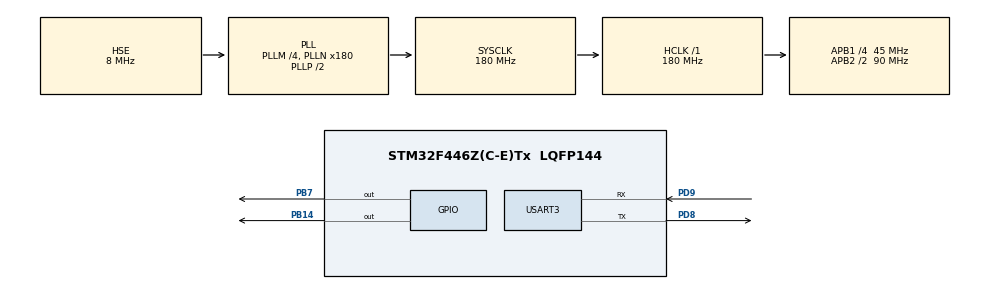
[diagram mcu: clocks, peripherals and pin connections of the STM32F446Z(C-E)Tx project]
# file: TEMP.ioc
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Dma.Request0=USART3_TX
Dma.USART3_TX.0.Direction=DMA_MEMORY_TO_PERIPH
Dma.USART3_TX.0.FIFOMode=DMA_FIFOMODE_DISABLE
Dma.USART3_TX.0.Instance=DMA1_Stream3
Dma.USART3_TX.0.MemDataAlignment=DMA_MDATAALIGN_BYTE
Dma.USART3_TX.0.MemInc=DMA_MINC_ENABLE
Dma.USART3_TX.0.Mode=DMA_NORMAL
Dma.USART3_TX.0.PeriphDataAlignment=DMA_PDATAALIGN_BYTE
Dma.USART3_TX.0.PeriphInc=DMA_PINC_DISABLE
Dma.USART3_TX.0.Priority=DMA_PRIORITY_LOW
Mcu.Family=STM32F4
Mcu.Name=STM32F446Z(C-E)Tx
Mcu.Package=LQFP144
NVIC.DMA1_Stream3_IRQn=true\:0\:0\:false\:false\:true\:false\:true\:true
NVIC.PriorityGroup=NVIC_PRIORITYGROUP_4
NVIC.USART3_IRQn=true\:0\:0\:false\:false\:true\:true\:true\:true
PB14.Signal=GPIO_Output
PB7.Signal=GPIO_Output
PD8.Mode=Asynchronous
PD8.Signal=USART3_TX
PD9.Mode=Asynchronous
PD9.Signal=USART3_RX
PH0-OSC_IN.Mode=HSE-External-Oscillator
PH0-OSC_IN.Signal=RCC_OSC_IN
PH1-OSC_OUT.Mode=HSE-External-Oscillator
PH1-OSC_OUT.Signal=RCC_OSC_OUT
ProjectManager.HeapSize=0x200
ProjectManager.StackSize=0x400
ProjectManager.TargetToolchain=STM32CubeIDE
RCC.AHBFreq_Value=180000000
RCC.APB1CLKDivider=RCC_HCLK_DIV4
RCC.APB1Freq_Value=45000000
RCC.APB1TimFreq_Value=90000000
RCC.APB2CLKDivider=RCC_HCLK_DIV2
RCC.APB2Freq_Value=90000000
RCC.APB2TimFreq_Value=180000000
RCC.CortexFreq_Value=180000000
RCC.HCLKFreq_Value=180000000
RCC.HSE_VALUE=8000000
RCC.PLLM=4
RCC.PLLN=180
RCC.PLLSourceVirtual=RCC_PLLSOURCE_HSE
RCC.SYSCLKFreq_VALUE=180000000
RCC.SYSCLKSource=RCC_SYSCLKSOURCE_PLLCLK
RCC.USBFreq_Value=180000000
RCC.VCOOutputFreq_Value=360000000
USART3.VirtualMode=VM_ASYNC
board=custom

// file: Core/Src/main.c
/* USER CODE BEGIN Header */
/**
  ******************************************************************************
  * @file           : main.c
  * @brief          : Main program body
  ******************************************************************************
  * @attention
  *
  * Copyright (c) 2026 STMicroelectronics.
  * All rights reserved.
  *
  * This software is licensed under terms that can be found in the LICENSE file
  * in the root directory of this software component.
  * If no LICENSE file comes with this software, it is provided AS-IS.
  *
  ******************************************************************************
  */
/* USER CODE END Header */
#include "main.h"

/* USER CODE BEGIN Includes */
#include <stdio.h>
uint8_t TxData[10240];
int isSent = 1;
int countloop = 0;
int countintterupt = 0;
void HAL_UART_TxCpltCallback(UART_HandleTypeDef *huart)
{
	isSent = 1;
	countintterupt++;
}
/* USER CODE END Includes */

UART_HandleTypeDef huart3;
DMA_HandleTypeDef hdma_usart3_tx;

void SystemClock_Config(void);
static void MX_GPIO_Init(void);
static void MX_DMA_Init(void);
static void MX_USART3_UART_Init(void);

int main(void)
{

  /* MCU Configuration--------------------------------------------------------*/

  /* Reset of all peripherals, Initializes the Flash interface and the Systick. */
  HAL_Init();

  /* Configure the system clock */
  SystemClock_Config();

  /* Initialize all configured peripherals */
  MX_GPIO_Init();
  MX_DMA_Init();
  MX_USART3_UART_Init();
  /* USER CODE BEGIN 2 */
  for(uint32_t i=0;i<10240;i++)
  {
	  TxData[i] = i&(0xff);
  }
  /* USER CODE END 2 */

  /* Infinite loop */
  while (1)
  {
//	  HAL_UART_Transmit(&huart3, TxData, 10240, HAL_MAX_DELAY);
//	  if(isSent == 1)
//	  {
//		  HAL_UART_Transmit_IT(&huart3, TxData, 10240);
//		  isSent = 0;
//		  countloop++;
//	  }
	  if(isSent == 1)
	  	  {
	  		  HAL_UART_Transmit_DMA(&huart3, TxData, 10240);
	  		  isSent = 0;
	  		  countloop++;
	  	  }
	  HAL_GPIO_TogglePin(GPIOB, GPIO_PIN_7);
	  HAL_Delay(100);
  }
}

void SystemClock_Config(void)
{
  RCC_OscInitTypeDef RCC_OscInitStruct = {0};
  RCC_ClkInitTypeDef RCC_ClkInitStruct = {0};

  /** Configure the main internal regulator output voltage
  */
  __HAL_RCC_PWR_CLK_ENABLE();
  __HAL_PWR_VOLTAGESCALING_CONFIG(PWR_REGULATOR_VOLTAGE_SCALE1);

  /** Initializes the RCC Oscillators according to the specified parameters
  * in the RCC_OscInitTypeDef structure.
  */
  RCC_OscInitStruct.OscillatorType = RCC_OSCILLATORTYPE_HSE;
  RCC_OscInitStruct.HSEState = RCC_HSE_ON;
  RCC_OscInitStruct.PLL.PLLState = RCC_PLL_ON;
  RCC_OscInitStruct.PLL.PLLSource = RCC_PLLSOURCE_HSE;
  RCC_OscInitStruct.PLL.PLLM = 4;
  RCC_OscInitStruct.PLL.PLLN = 180;
  RCC_OscInitStruct.PLL.PLLP = RCC_PLLP_DIV2;
  RCC_OscInitStruct.PLL.PLLQ = 2;
  RCC_OscInitStruct.PLL.PLLR = 2;
  if (HAL_RCC_OscConfig(&RCC_OscInitStruct) != HAL_OK)
  {
    Error_Handler();
  }

  /** Activate the Over-Drive mode
  */
  if (HAL_PWREx_EnableOverDrive() != HAL_OK)
  {
    Error_Handler();
  }

  /** Initializes the CPU, AHB and APB buses clocks
  */
  RCC_ClkInitStruct.ClockType = RCC_CLOCKTYPE_HCLK|RCC_CLOCKTYPE_SYSCLK
                              |RCC_CLOCKTYPE_PCLK1|RCC_CLOCKTYPE_PCLK2;
  RCC_ClkInitStruct.SYSCLKSource = RCC_SYSCLKSOURCE_PLLCLK;
  RCC_ClkInitStruct.AHBCLKDivider = RCC_SYSCLK_DIV1;
  RCC_ClkInitStruct.APB1CLKDivider = RCC_HCLK_DIV4;
  RCC_ClkInitStruct.APB2CLKDivider = RCC_HCLK_DIV2;

  if (HAL_RCC_ClockConfig(&RCC_ClkInitStruct, FLASH_LATENCY_5) != HAL_OK)
  {
    Error_Handler();
  }
}

static void MX_USART3_UART_Init(void)
{

  huart3.Instance = USART3;
  huart3.Init.BaudRate = 115200;
  huart3.Init.WordLength = UART_WORDLENGTH_8B;
  huart3.Init.StopBits = UART_STOPBITS_1;
  huart3.Init.Parity = UART_PARITY_NONE;
  huart3.Init.Mode = UART_MODE_TX_RX;
  huart3.Init.HwFlowCtl = UART_HWCONTROL_NONE;
  huart3.Init.OverSampling = UART_OVERSAMPLING_16;
  if (HAL_UART_Init(&huart3) != HAL_OK)
  {
    Error_Handler();
  }

}

static void MX_DMA_Init(void)
{

  /* DMA controller clock enable */
  __HAL_RCC_DMA1_CLK_ENABLE();

  /* DMA interrupt init */
  /* DMA1_Stream3_IRQn interrupt configuration */
  HAL_NVIC_SetPriority(DMA1_Stream3_IRQn, 0, 0);
  HAL_NVIC_EnableIRQ(DMA1_Stream3_IRQn);

}

static void MX_GPIO_Init(void)
{
  GPIO_InitTypeDef GPIO_InitStruct = {0};

  /* GPIO Ports Clock Enable */
  __HAL_RCC_GPIOH_CLK_ENABLE();
  __HAL_RCC_GPIOB_CLK_ENABLE();
  __HAL_RCC_GPIOD_CLK_ENABLE();

  /*Configure GPIO pin Output Level */
  HAL_GPIO_WritePin(GPIOB, GPIO_PIN_14|GPIO_PIN_7, GPIO_PIN_RESET);

  /*Configure GPIO pins : PB14 PB7 */
  GPIO_InitStruct.Pin = GPIO_PIN_14|GPIO_PIN_7;
  GPIO_InitStruct.Mode = GPIO_MODE_OUTPUT_PP;
  GPIO_InitStruct.Pull = GPIO_NOPULL;
  GPIO_InitStruct.Speed = GPIO_SPEED_FREQ_LOW;
  HAL_GPIO_Init(GPIOB, &GPIO_InitStruct);

}

void Error_Handler(void)
{
  __disable_irq();
  while (1)
  {
  }
}
